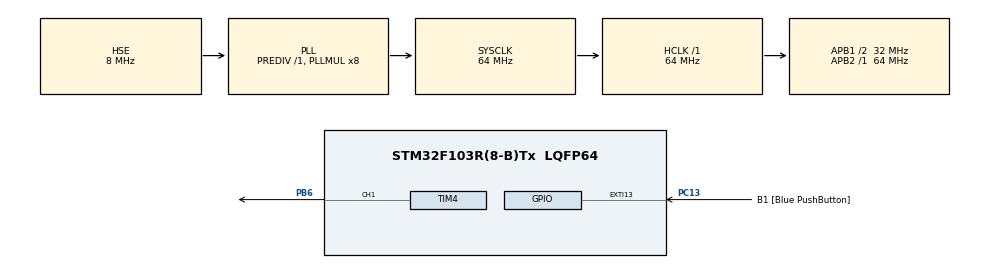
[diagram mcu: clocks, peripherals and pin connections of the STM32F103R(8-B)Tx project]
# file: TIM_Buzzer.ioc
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Mcu.Family=STM32F1
Mcu.Name=STM32F103R(8-B)Tx
Mcu.Package=LQFP64
NVIC.EXTI15_10_IRQn=true\:0\:0\:false\:false\:true\:true\:true\:true
NVIC.PriorityGroup=NVIC_PRIORITYGROUP_4
PA13.GPIO_Label=TMS
PA13.Mode=Serial_Wire
PA13.Signal=SYS_JTMS-SWDIO
PA14.GPIO_Label=TCK
PA14.Mode=Serial_Wire
PA14.Signal=SYS_JTCK-SWCLK
PB3.GPIO_Label=SWO
PB3.Signal=SYS_JTDO-TRACESWO
PB6.Signal=S_TIM4_CH1
PC13-TAMPER-RTC.GPIO_Label=B1 [Blue PushButton]
PC13-TAMPER-RTC.GPIO_PuPd=GPIO_NOPULL
PC13-TAMPER-RTC.Signal=GPXTI13
PC14-OSC32_IN.Mode=LSE-External-Oscillator
PC14-OSC32_IN.Signal=RCC_OSC32_IN
PC15-OSC32_OUT.Mode=LSE-External-Oscillator
PC15-OSC32_OUT.Signal=RCC_OSC32_OUT
PD0-OSC_IN.Mode=HSE-External-Clock-Source
PD0-OSC_IN.Signal=RCC_OSC_IN
PD1-OSC_OUT.Mode=HSE-External-Clock-Source
PD1-OSC_OUT.Signal=RCC_OSC_OUT
ProjectManager.HeapSize=0x200
ProjectManager.StackSize=0x400
ProjectManager.TargetToolchain=STM32CubeIDE
RCC.AHBFreq_Value=64000000
RCC.APB1CLKDivider=RCC_HCLK_DIV2
RCC.APB1Freq_Value=32000000
RCC.APB1TimFreq_Value=64000000
RCC.APB2Freq_Value=64000000
RCC.APB2TimFreq_Value=64000000
RCC.HCLKFreq_Value=64000000
RCC.PLLMUL=RCC_PLL_MUL8
RCC.PLLSourceVirtual=RCC_PLLSOURCE_HSE
RCC.RTCClockSelection=RCC_RTCCLKSOURCE_LSE
RCC.SYSCLKFreq_VALUE=64000000
RCC.SYSCLKSource=RCC_SYSCLKSOURCE_PLLCLK
RCC.USBFreq_Value=64000000
SH.S_TIM4_CH1.0=TIM4_CH1,PWM Generation1 CH1
TIM4.Channel-PWM\ Generation1\ CH1=TIM_CHANNEL_1
TIM4.Period=0
TIM4.Prescaler=63
VP_TIM4_VS_ClockSourceINT.Mode=Internal
board=NUCLEO-F103RB

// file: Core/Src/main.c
/* USER CODE BEGIN Header */
/**
  ******************************************************************************
  * @file           : main.c
  * @brief          : Main program body
  ******************************************************************************
  * @attention
  *
  * Copyright (c) 2024 STMicroelectronics.
  * All rights reserved.
  *
  * This software is licensed under terms that can be found in the LICENSE file
  * in the root directory of this software component.
  * If no LICENSE file comes with this software, it is provided AS-IS.
  *
  ******************************************************************************
  */
/* USER CODE END Header */
#include "main.h"

/* USER CODE BEGIN PM */
#define	TIM2COUNTERCLOCK	1000000
/* USER CODE END PM */

TIM_HandleTypeDef htim4;

/* USER CODE BEGIN PV */

enum notes
{
	C4 = 26163,	// 261.63Hz
	D4 = 29366,
	E4 = 32963,
	F4 = 34923,
	G4 = 39200,
	A4 = 44000,
	B4 = 49388,
	C5 = 52325
};

/* SCHOOLBELL */
enum notes SchoolBell[] = {
		G4, G4, A4, A4, G4, G4, E4, G4, G4, E4, E4, D4,
		G4, G4, A4, A4, G4, G4, E4, G4, E4, D4, E4, C4
};

/* USER CODE END PV */

void SystemClock_Config(void);
static void MX_GPIO_Init(void);
static void MX_TIM4_Init(void);

int main(void)
{

  /* MCU Configuration--------------------------------------------------------*/

  /* Reset of all peripherals, Initializes the Flash interface and the Systick. */
  HAL_Init();

  /* Configure the system clock */
  SystemClock_Config();

  /* Initialize all configured peripherals */
  MX_GPIO_Init();
  MX_TIM4_Init();
  /* USER CODE BEGIN 2 */

  /* play */
  for(uint8_t i = 0; i < sizeof(SchoolBell) / sizeof(enum notes); i++)
  {
	  /* set the PWM period */
	  __HAL_TIM_SET_AUTORELOAD(&htim4, (int)(TIM2COUNTERCLOCK / SchoolBell[i] * 100));

	  /* set the PWM pulse */
	  __HAL_TIM_SET_COMPARE(&htim4, TIM_CHANNEL_1, TIM2COUNTERCLOCK / SchoolBell[i] * 100 / 2);

	  HAL_TIM_PWM_Start(&htim4, TIM_CHANNEL_1);
	  HAL_Delay(500);

	  /* interval between notes */
	  HAL_TIM_PWM_Stop(&htim4, TIM_CHANNEL_1);
	  HAL_Delay(10);
  }

  /* USER CODE END 2 */

  /* Infinite loop */
  while (1)
  {

  }
}

void SystemClock_Config(void)
{
  RCC_OscInitTypeDef RCC_OscInitStruct = {0};
  RCC_ClkInitTypeDef RCC_ClkInitStruct = {0};

  /** Initializes the RCC Oscillators according to the specified parameters
  * in the RCC_OscInitTypeDef structure.
  */
  RCC_OscInitStruct.OscillatorType = RCC_OSCILLATORTYPE_HSE;
  RCC_OscInitStruct.HSEState = RCC_HSE_BYPASS;
  RCC_OscInitStruct.HSEPredivValue = RCC_HSE_PREDIV_DIV1;
  RCC_OscInitStruct.HSIState = RCC_HSI_ON;
  RCC_OscInitStruct.PLL.PLLState = RCC_PLL_ON;
  RCC_OscInitStruct.PLL.PLLSource = RCC_PLLSOURCE_HSE;
  RCC_OscInitStruct.PLL.PLLMUL = RCC_PLL_MUL8;
  if (HAL_RCC_OscConfig(&RCC_OscInitStruct) != HAL_OK)
  {
    Error_Handler();
  }

  /** Initializes the CPU, AHB and APB buses clocks
  */
  RCC_ClkInitStruct.ClockType = RCC_CLOCKTYPE_HCLK|RCC_CLOCKTYPE_SYSCLK
                              |RCC_CLOCKTYPE_PCLK1|RCC_CLOCKTYPE_PCLK2;
  RCC_ClkInitStruct.SYSCLKSource = RCC_SYSCLKSOURCE_PLLCLK;
  RCC_ClkInitStruct.AHBCLKDivider = RCC_SYSCLK_DIV1;
  RCC_ClkInitStruct.APB1CLKDivider = RCC_HCLK_DIV2;
  RCC_ClkInitStruct.APB2CLKDivider = RCC_HCLK_DIV1;

  if (HAL_RCC_ClockConfig(&RCC_ClkInitStruct, FLASH_LATENCY_2) != HAL_OK)
  {
    Error_Handler();
  }
}

static void MX_TIM4_Init(void)
{

  TIM_ClockConfigTypeDef sClockSourceConfig = {0};
  TIM_MasterConfigTypeDef sMasterConfig = {0};
  TIM_OC_InitTypeDef sConfigOC = {0};

  htim4.Instance = TIM4;
  htim4.Init.Prescaler = 63;
  htim4.Init.CounterMode = TIM_COUNTERMODE_UP;
  htim4.Init.Period = 0;
  htim4.Init.ClockDivision = TIM_CLOCKDIVISION_DIV1;
  htim4.Init.AutoReloadPreload = TIM_AUTORELOAD_PRELOAD_DISABLE;
  if (HAL_TIM_Base_Init(&htim4) != HAL_OK)
  {
    Error_Handler();
  }
  sClockSourceConfig.ClockSource = TIM_CLOCKSOURCE_INTERNAL;
  if (HAL_TIM_ConfigClockSource(&htim4, &sClockSourceConfig) != HAL_OK)
  {
    Error_Handler();
  }
  if (HAL_TIM_PWM_Init(&htim4) != HAL_OK)
  {
    Error_Handler();
  }
  sMasterConfig.MasterOutputTrigger = TIM_TRGO_RESET;
  sMasterConfig.MasterSlaveMode = TIM_MASTERSLAVEMODE_DISABLE;
  if (HAL_TIMEx_MasterConfigSynchronization(&htim4, &sMasterConfig) != HAL_OK)
  {
    Error_Handler();
  }
  sConfigOC.OCMode = TIM_OCMODE_PWM1;
  sConfigOC.Pulse = 0;
  sConfigOC.OCPolarity = TIM_OCPOLARITY_HIGH;
  sConfigOC.OCFastMode = TIM_OCFAST_DISABLE;
  if (HAL_TIM_PWM_ConfigChannel(&htim4, &sConfigOC, TIM_CHANNEL_1) != HAL_OK)
  {
    Error_Handler();
  }
  HAL_TIM_MspPostInit(&htim4);

}

static void MX_GPIO_Init(void)
{
  GPIO_InitTypeDef GPIO_InitStruct = {0};

  /* GPIO Ports Clock Enable */
  __HAL_RCC_GPIOC_CLK_ENABLE();
  __HAL_RCC_GPIOD_CLK_ENABLE();
  __HAL_RCC_GPIOA_CLK_ENABLE();
  __HAL_RCC_GPIOB_CLK_ENABLE();

  /*Configure GPIO pin : B1_Pin */
  GPIO_InitStruct.Pin = B1_Pin;
  GPIO_InitStruct.Mode = GPIO_MODE_IT_RISING;
  GPIO_InitStruct.Pull = GPIO_NOPULL;
  HAL_GPIO_Init(B1_GPIO_Port, &GPIO_InitStruct);

  /* EXTI interrupt init*/
  HAL_NVIC_SetPriority(EXTI15_10_IRQn, 0, 0);
  HAL_NVIC_EnableIRQ(EXTI15_10_IRQn);

}

void Error_Handler(void)
{
  __disable_irq();
  while (1)
  {
  }
}
